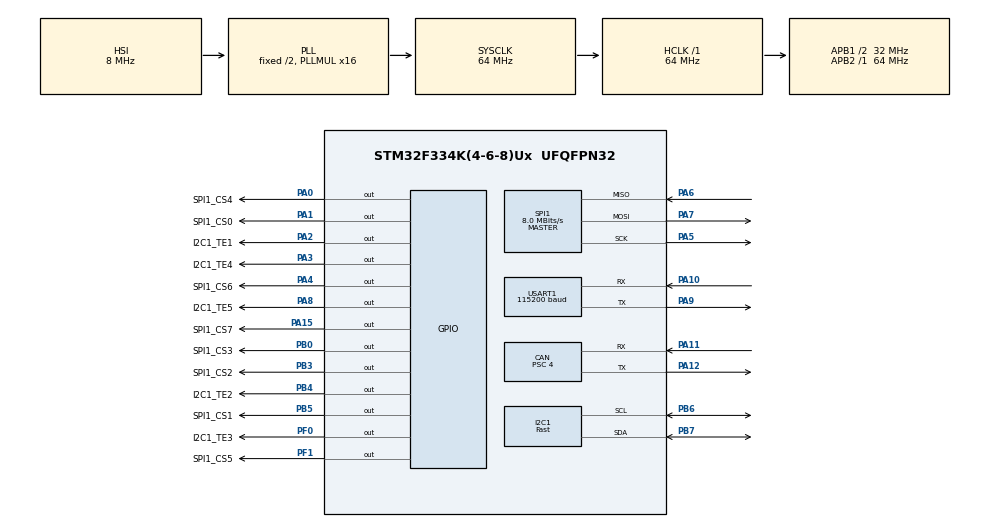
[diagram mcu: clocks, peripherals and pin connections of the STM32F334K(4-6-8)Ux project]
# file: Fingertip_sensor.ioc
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CAN.BS1=CAN_BS1_3TQ
CAN.BS2=CAN_BS2_4TQ
CAN.CalculateBaudRate=1000000
CAN.CalculateTimeBit=1000
CAN.CalculateTimeQuantum=125.0
CAN.Prescaler=4
I2C1.I2C_Speed_Mode=I2C_Fast
I2C1.Timing=0x0000020B
Mcu.Family=STM32F3
Mcu.Name=STM32F334K(4-6-8)Ux
Mcu.Package=UFQFPN32
NVIC.CAN_TX_IRQn=true\:0\:0\:false\:false\:true\:true\:true\:true
NVIC.PriorityGroup=NVIC_PRIORITYGROUP_4
NVIC.TIM2_IRQn=true\:0\:0\:false\:false\:true\:true\:true\:true
NVIC.TIM3_IRQn=true\:0\:0\:false\:false\:true\:true\:true\:true
PA0.GPIO_Label=SPI1_CS4
PA0.Signal=GPIO_Output
PA1.GPIO_Label=SPI1_CS0
PA1.Signal=GPIO_Output
PA10.Mode=Asynchronous
PA10.Signal=USART1_RX
PA11.Mode=CAN_Activate
PA11.Signal=CAN_RX
PA12.Mode=CAN_Activate
PA12.Signal=CAN_TX
PA15.GPIO_Label=SPI1_CS7
PA15.Signal=GPIO_Output
PA2.GPIO_Label=I2C1_TE1
PA2.Signal=GPIO_Output
PA3.GPIO_Label=I2C1_TE4
PA3.Signal=GPIO_Output
PA4.GPIO_Label=SPI1_CS6
PA4.Signal=GPIO_Output
PA5.Mode=Full_Duplex_Master
PA5.Signal=SPI1_SCK
PA6.Mode=Full_Duplex_Master
PA6.Signal=SPI1_MISO
PA7.Mode=Full_Duplex_Master
PA7.Signal=SPI1_MOSI
PA8.GPIO_Label=I2C1_TE5
PA8.Signal=GPIO_Output
PA9.Mode=Asynchronous
PA9.Signal=USART1_TX
PB0.GPIO_Label=SPI1_CS3
PB0.Signal=GPIO_Output
PB3.GPIO_Label=SPI1_CS2
PB3.Signal=GPIO_Output
PB4.GPIO_Label=I2C1_TE2
PB4.Signal=GPIO_Output
PB5.GPIO_Label=SPI1_CS1
PB5.Signal=GPIO_Output
PB6.Mode=I2C
PB6.Signal=I2C1_SCL
PB7.Mode=I2C
PB7.Signal=I2C1_SDA
PF0\ /\ OSC_IN.GPIO_Label=I2C1_TE3
PF0\ /\ OSC_IN.Signal=GPIO_Output
PF1\ /\ OSC_OUT.GPIO_Label=SPI1_CS5
PF1\ /\ OSC_OUT.Signal=GPIO_Output
ProjectManager.HeapSize=0x200
ProjectManager.StackSize=0x400
ProjectManager.TargetToolchain=STM32CubeIDE
RCC.AHBFreq_Value=64000000
RCC.APB1CLKDivider=RCC_HCLK_DIV2
RCC.APB1Freq_Value=32000000
RCC.APB1TimFreq_Value=64000000
RCC.APB2Freq_Value=64000000
RCC.APB2TimFreq_Value=64000000
RCC.CortexFreq_Value=64000000
RCC.HCLKFreq_Value=64000000
RCC.HSE_VALUE=8000000
RCC.HSI_VALUE=8000000
RCC.PLLMUL=RCC_PLL_MUL16
RCC.SYSCLKFreq_VALUE=64000000
RCC.SYSCLKSourceVirtual=RCC_SYSCLKSOURCE_PLLCLK
SPI1.BaudRatePrescaler=SPI_BAUDRATEPRESCALER_8
SPI1.CalculateBaudRate=8.0 MBits/s
SPI1.DataSize=SPI_DATASIZE_8BIT
SPI1.Direction=SPI_DIRECTION_2LINES
SPI1.Mode=SPI_MODE_MASTER
SPI1.NSSPMode=SPI_NSS_PULSE_DISABLE
SPI1.VirtualType=VM_MASTER
TIM15.Prescaler=64
TIM2.Period=100000
TIM2.Prescaler=64
TIM3.Prescaler=64
USART1.BaudRate=115200
USART1.VirtualMode-Asynchronous=VM_ASYNC
VP_TIM15_VS_ClockSourceINT.Mode=Internal
VP_TIM2_VS_ClockSourceINT.Mode=Internal
VP_TIM3_VS_ClockSourceINT.Mode=Internal
board=custom

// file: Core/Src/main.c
/* USER CODE BEGIN Header */
/**
  ******************************************************************************
  * @file           : main.c
  * @brief          : Main program body
  ******************************************************************************
  * @attention
  *
  * Copyright (c) 2023 STMicroelectronics.
  * All rights reserved.
  *
  * This software is licensed under terms that can be found in the LICENSE file
  * in the root directory of this software component.
  * If no LICENSE file comes with this software, it is provided AS-IS.
  *
  ******************************************************************************
  */
/* USER CODE END Header */
#include "main.h"
#include "can.h"
#include "i2c.h"
#include "spi.h"
#include "tim.h"
#include "usart.h"
#include "gpio.h"

/* USER CODE BEGIN Includes */
#include "fingertip.h"
/* USER CODE END Includes */

void SystemClock_Config(void);

int main(void)
{

  /* MCU Configuration--------------------------------------------------------*/

  /* Reset of all peripherals, Initializes the Flash interface and the Systick. */
  HAL_Init();

  /* Configure the system clock */
  SystemClock_Config();

  /* Initialize all configured peripherals */
  MX_GPIO_Init();
  MX_CAN_Init();
  MX_I2C1_Init();
  MX_SPI1_Init();
  MX_USART1_UART_Init();
  MX_TIM2_Init();
  MX_TIM3_Init();
  MX_TIM15_Init();
  /* USER CODE BEGIN 2 */
  HAL_TIM_Base_Start_IT(&htim2);
  HAL_TIM_Base_Start(&htim3);
  HAL_TIM_Base_Start(&htim15);
  /* USER CODE END 2 */

  /* Infinite loop */
  /* USER CODE BEGIN WHILE */

  //printf("\n\rStarting fingertip sensor...\n\r");
  fingertip_main();

  while (1)
  {
    /* USER CODE END WHILE */

    /* USER CODE BEGIN 3 */
	//printf("Hello World from Main!\n\r");
	HAL_Delay(1000);

  }
  /* USER CODE END 3 */
}

void SystemClock_Config(void)
{
  RCC_OscInitTypeDef RCC_OscInitStruct = {0};
  RCC_ClkInitTypeDef RCC_ClkInitStruct = {0};
  RCC_PeriphCLKInitTypeDef PeriphClkInit = {0};

  /** Initializes the RCC Oscillators according to the specified parameters
  * in the RCC_OscInitTypeDef structure.
  */
  RCC_OscInitStruct.OscillatorType = RCC_OSCILLATORTYPE_HSI;
  RCC_OscInitStruct.HSIState = RCC_HSI_ON;
  RCC_OscInitStruct.HSICalibrationValue = RCC_HSICALIBRATION_DEFAULT;
  RCC_OscInitStruct.PLL.PLLState = RCC_PLL_ON;
  RCC_OscInitStruct.PLL.PLLSource = RCC_PLLSOURCE_HSI;
  RCC_OscInitStruct.PLL.PLLMUL = RCC_PLL_MUL16;
  if (HAL_RCC_OscConfig(&RCC_OscInitStruct) != HAL_OK)
  {
    Error_Handler();
  }

  /** Initializes the CPU, AHB and APB buses clocks
  */
  RCC_ClkInitStruct.ClockType = RCC_CLOCKTYPE_HCLK|RCC_CLOCKTYPE_SYSCLK
                              |RCC_CLOCKTYPE_PCLK1|RCC_CLOCKTYPE_PCLK2;
  RCC_ClkInitStruct.SYSCLKSource = RCC_SYSCLKSOURCE_PLLCLK;
  RCC_ClkInitStruct.AHBCLKDivider = RCC_SYSCLK_DIV1;
  RCC_ClkInitStruct.APB1CLKDivider = RCC_HCLK_DIV2;
  RCC_ClkInitStruct.APB2CLKDivider = RCC_HCLK_DIV1;

  if (HAL_RCC_ClockConfig(&RCC_ClkInitStruct, FLASH_LATENCY_2) != HAL_OK)
  {
    Error_Handler();
  }
  PeriphClkInit.PeriphClockSelection = RCC_PERIPHCLK_USART1|RCC_PERIPHCLK_I2C1;
  PeriphClkInit.Usart1ClockSelection = RCC_USART1CLKSOURCE_PCLK1;
  PeriphClkInit.I2c1ClockSelection = RCC_I2C1CLKSOURCE_HSI;
  if (HAL_RCCEx_PeriphCLKConfig(&PeriphClkInit) != HAL_OK)
  {
    Error_Handler();
  }
}

void Error_Handler(void)
{
  __disable_irq();
  while (1)
  {
  }
}
